# STM32L4x3 register map
File version: 1.3
CPU: CM4 r1p0, little endian, no MPU, no FPU, 3 interrupt priority bits
Registers are 32-bit, read-write, reset 0x0 unless marked. A register's access mark holds for its fields unless they carry their own. Offsets are from the block's base; [hi:lo] are bit positions; {n}, {i} and the like mark numbered series.

## SPI1 — Serial peripheral interface/Inter-IC sound
Base 0x40013000
Same registers: SPI2 0x40003800, SPI3 0x40003C00
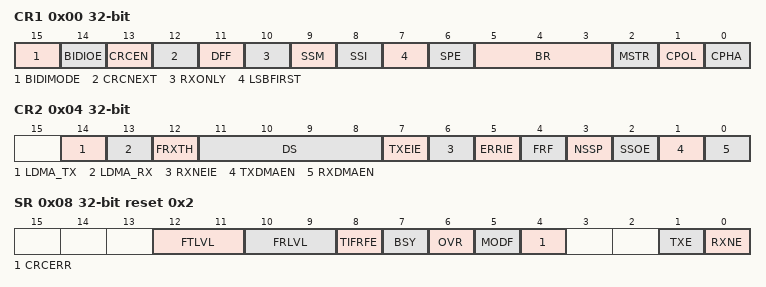
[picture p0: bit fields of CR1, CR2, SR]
0x00 CR1 — control register 1
  [15] BIDIMODE — Bidirectional data mode enable
  [14] BIDIOE — Output enable in bidirectional mode
  [13] CRCEN — Hardware CRC calculation enable
  [12] CRCNEXT — CRC transfer next
  [11] DFF — Data frame format
  [10] RXONLY — Receive only
  [9] SSM — Software slave management
  [8] SSI — Internal slave select
  [7] LSBFIRST — Frame format
  [6] SPE — SPI enable
  [5:3] BR — Baud rate control
  [2] MSTR — Master selection
  [1] CPOL — Clock polarity
  [0] CPHA — Clock phase
0x04 CR2 — control register 2
  [14] LDMA_TX — Last DMA transfer for transmission
  [13] LDMA_RX — Last DMA transfer for reception
  [12] FRXTH — FIFO reception threshold
  [11:8] DS — Data size
  [7] TXEIE — Tx buffer empty interrupt enable
  [6] RXNEIE — RX buffer not empty interrupt enable
  [5] ERRIE — Error interrupt enable
  [4] FRF — Frame format
  [3] NSSP — NSS pulse management
  [2] SSOE — SS output enable
  [1] TXDMAEN — Tx buffer DMA enable
  [0] RXDMAEN — Rx buffer DMA enable
0x08 SR access per field reset 0x2 — status register
  [12:11] FTLVL ro — FIFO transmission level
  [10:9] FRLVL ro — FIFO reception level
  [8] TIFRFE ro — TI frame format error
  [7] BSY ro — Busy flag
  [6] OVR ro — Overrun flag
  [5] MODF ro — Mode fault
  [4] CRCERR rw — CRC error flag
  [1] TXE ro — Transmit buffer empty
  [0] RXNE ro — Receive buffer not empty
0x0C DR — data register
  [15:0] DR — Data register
0x10 CRCPR reset 0x7 — CRC polynomial register
  [15:0] CRCPOLY
0x14 RXCRCR ro — RX CRC register
  [15:0] RxCRC
0x18 TXCRCR ro — TX CRC register
  [15:0] TxCRC

## EXTI — External interrupt/event controller
Base 0x40010400
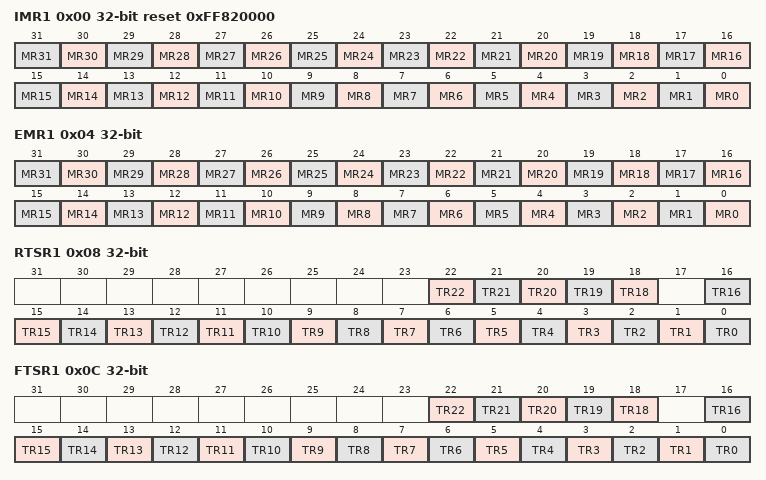
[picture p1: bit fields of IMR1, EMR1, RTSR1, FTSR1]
0x00 IMR1 reset 0xFF820000 — Interrupt mask register
  [n] MR{n} (n=0..31) — Interrupt Mask on line {n}
0x04 EMR1 — Event mask register
  [n] MR{n} (n=0..31) — Event Mask on line {n}
0x08 RTSR1 — Rising Trigger selection register
  [n] TR{n} (n=18..22) — Rising trigger event configuration of line {n}
  [n] TR{n} (n=0..16) — Rising trigger event configuration of line {n}
0x0C FTSR1 — Falling Trigger selection register
  [n] TR{n} (n=18..22) — Falling trigger event configuration of line {n}
  [n] TR{n} (n=0..16) — Falling trigger event configuration of line {n}
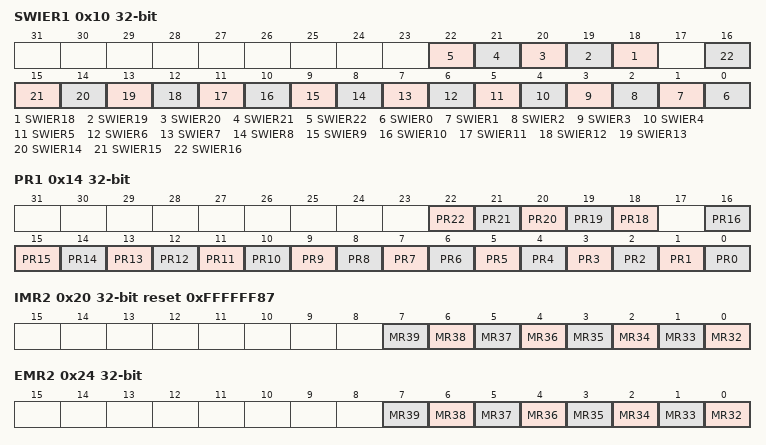
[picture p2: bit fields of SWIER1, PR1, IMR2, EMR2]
0x10 SWIER1 — Software interrupt event register
  [n] SWIER{n} (n=18..22) — Software Interrupt on line {n}
  [n] SWIER{n} (n=0..16) — Software Interrupt on line {n}
0x14 PR1 — Pending register
  [n] PR{n} (n=18..22) — Pending bit {n}
  [n] PR{n} (n=0..16) — Pending bit {n}
0x20 IMR2 reset 0xFFFFFF87 — Interrupt mask register
  [n-32] MR{n} (n=32..39) — Interrupt Mask on external/internal line {n}
0x24 EMR2 — Event mask register
  [n-32] MR{n} (n=32..39) — Event mask on external/internal line {n}
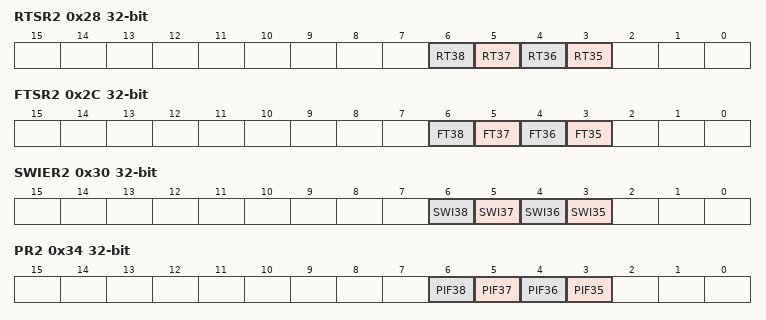
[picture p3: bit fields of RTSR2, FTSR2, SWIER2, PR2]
0x28 RTSR2 — Rising Trigger selection register
  [n-32] RT{n} (n=35..38) — Rising trigger event configuration bit of line {n}
0x2C FTSR2 — Falling Trigger selection register
  [n-32] FT{n} (n=35..38) — Falling trigger event configuration bit of line {n}
0x30 SWIER2 — Software interrupt event register
  [n-32] SWI{n} (n=35..38) — Software interrupt on line {n}
0x34 PR2 — Pending register
  [n-32] PIF{n} (n=35..38) — Pending interrupt flag on line {n}

## VREFBUF — Voltage reference buffer
Base 0x40010030
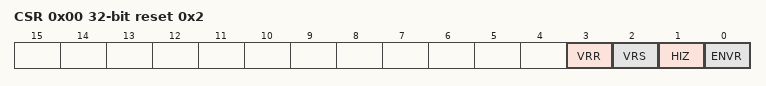
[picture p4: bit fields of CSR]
0x00 CSR access per field reset 0x2 — VREF control and status register
  [3] VRR ro — Voltage reference buffer ready
  [2] VRS rw — Voltage reference scale
  [1] HIZ rw — High impedance mode
  [0] ENVR rw — Voltage reference buffer enable
0x04 CCR — calibration control register
  [5:0] TRIM — Trimming code
